AUTOSAR XML (schema 4-0-3)
package /ComponentTypes
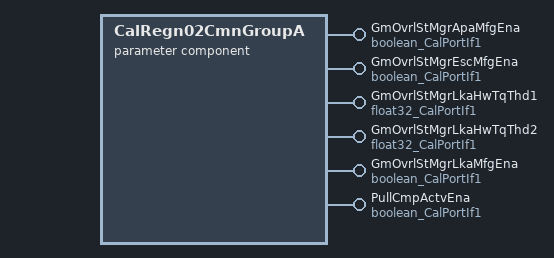
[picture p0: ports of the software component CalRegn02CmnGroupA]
  parameter sw component type CalRegn02CmnGroupA
    6 x provide port:
      GmOvrlStMgrApaMfgEna: parameter-provide-com-spec{init-value=0, parameter=Logl}, provided-interface=boolean_CalPortIf1
      GmOvrlStMgrEscMfgEna: parameter-provide-com-spec{init-value=0, parameter=Logl}, provided-interface=boolean_CalPortIf1
      GmOvrlStMgrLkaHwTqThd1: parameter-provide-com-spec{init-value=3, parameter=Val}, provided-interface=float32_CalPortIf1
      GmOvrlStMgrLkaHwTqThd2: parameter-provide-com-spec{init-value=5, parameter=Val}, provided-interface=float32_CalPortIf1
      GmOvrlStMgrLkaMfgEna: parameter-provide-com-spec{init-value=0, parameter=Logl}, provided-interface=boolean_CalPortIf1
      PullCmpActvEna: parameter-provide-com-spec{init-value=1, parameter=Logl}, provided-interface=boolean_CalPortIf1
